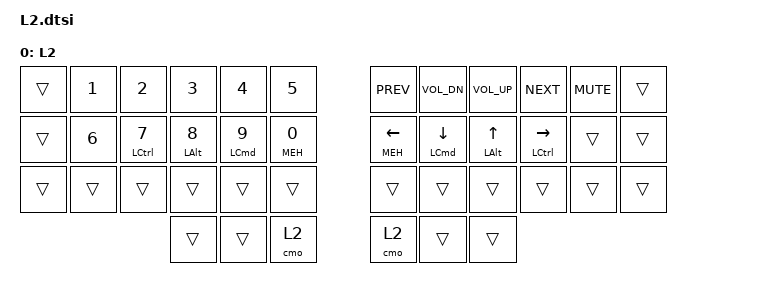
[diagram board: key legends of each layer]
/**
 * Numeric, Navigation and Media Controls Layer
 */

/ {
  keymap {
    compatible = "zmk,keymap";

    layer_2 {
      display-name = "L2";
      bindings = <
// ╭───────────────┬───────────────┬───────────────┬───────────────┬───────────────┬───────────────╮   ╭───────────────┬───────────────┬───────────────┬───────────────┬───────────────┬───────────────╮
// │0              │1              │2              │3              │4              │5              │   │6              │7              │8              │9              │10             │11             │
    &trans          &kp N1          &kp N2          &kp N3          &kp N4          &kp N5              &kp C_PREV      &kp C_VOL_DN    &kp C_VOL_UP    &kp C_NEXT      &kp C_MUTE      &trans
// ├───────────────├───────────────┼───────────────┼───────────────┼───────────────┼───────────────┤   ├───────────────├───────────────┼───────────────┼───────────────┼───────────────┼───────────────┤
// │12             │13             │14             │15             │16             │17             │   │18             │19             │20             │21             │22             │23             │
    &trans          &kp N6          &hrml LCTRL N7  &hrml LALT N8   &hrml LCMD N9   &hrml MEH N0        &hrmr MEH LEFT  &hrmr LCMD DOWN &hrmr LALT UP   &hrmr LCTRL RIGHT&trans         &trans
// ├───────────────├───────────────┼───────────────┼───────────────┼───────────────┼───────────────┤   ├───────────────├───────────────┼───────────────┼───────────────┼───────────────┼───────────────┤
// │24             │25             │26             │27             │28             │29             │   │30             │31             │32             │33             │34             │35             │
    &trans          &trans          &trans          &trans          &trans          &trans              &trans          &trans          &trans          &trans          &trans          &trans
// ╰───────────────┴───────────────┴───────────────┼───────────────┼───────────────┼───────────────┤   ├───────────────├───────────────┼───────────────┼───────────────┴───────────────┴───────────────╯
//                                                 │36             │37             │38             │   │39             │40             │41             │
                                                    &trans          &trans          &cmo L2             &cmo L2         &trans          &trans
//                                                 ╰───────────────┴───────────────┴───────────────╯   ╰───────────────┴───────────────┴───────────────╯
      >;
    };
  };
};
